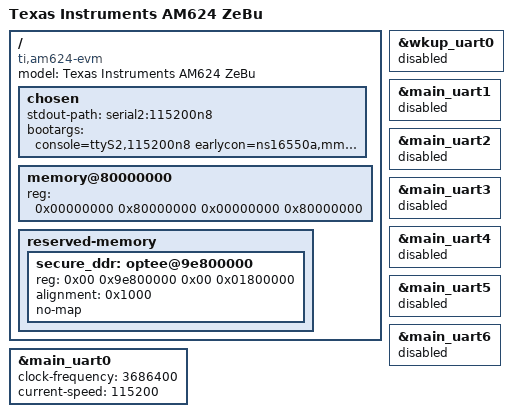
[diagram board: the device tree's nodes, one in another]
// SPDX-License-Identifier: GPL-2.0
/*
 * AM624 VLAB - www.ti.com/DOES"NTEXIST
 * Copyright (C) 2021 Texas Instruments Incorporated - https://www.ti.com/
 */

/dts-v1/;

#include <dt-bindings/leds/common.h>
#include <dt-bindings/gpio/gpio.h>
#include "k3-am624.dtsi"

/ {
	compatible =  "ti,am624-evm", "ti,am624";
	model = "Texas Instruments AM624 ZeBu";

	chosen {
		stdout-path = "serial2:115200n8";
		bootargs = "console=ttyS2,115200n8 earlycon=ns16550a,mmio32,0x02800000";
	};

	memory@80000000 {
		device_type = "memory";
		/* 2G RAM */
		reg = <0x00000000 0x80000000 0x00000000 0x80000000>;

	};

	reserved-memory {
		#address-cells = <2>;
		#size-cells = <2>;
		ranges;

		secure_ddr: optee@9e800000 {
			reg = <0x00 0x9e800000 0x00 0x01800000>; /* for OP-TEE */
			alignment = <0x1000>;
			no-map;
		};
	};
};

/* wkup_uart0 is reserved for firmware usage */
&wkup_uart0 {
	status = "reserved";
};

&main_uart0 {
	/* HACKITY to get /2 divisor for QT/Zebu transactors to work */
	clock-frequency = <3686400>;
	current-speed = <115200>;
};

/* main_uart1 is reserved for firmware usage */
&main_uart1 {
	status = "reserved";
};

&main_uart2 {
	status = "disabled";
};

&main_uart3 {
	status = "disabled";
};

&main_uart4 {
	status = "disabled";
};

&main_uart5 {
	status = "disabled";
};

&main_uart6 {
	status = "disabled";
};
